AUTOSAR XML (schema 314)
package /ComponentType
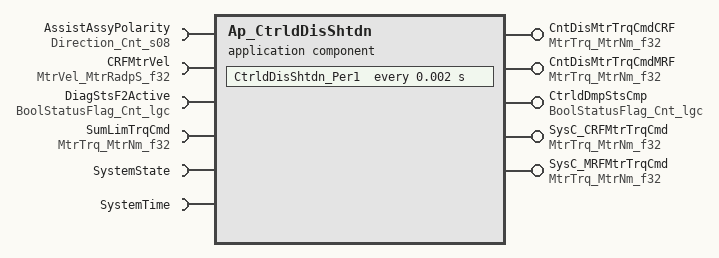
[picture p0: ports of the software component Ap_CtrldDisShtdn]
  application software component type Ap_CtrldDisShtdn
    5 x provide port:
      CntDisMtrTrqCmdCRF: unqueued-sender-com-spec{data-element=MtrNm_f32, can-invalidate=false, init-value=D_ZERO_ULS_F32}, provided-interface=MtrTrq_MtrNm_f32
      CntDisMtrTrqCmdMRF: unqueued-sender-com-spec{data-element=MtrNm_f32, can-invalidate=false, init-value=D_ZERO_ULS_F32}, provided-interface=MtrTrq_MtrNm_f32
      CtrldDmpStsCmp: unqueued-sender-com-spec{data-element=Cnt_lgc, can-invalidate=false, init-value=D_FALSE_CNT_LGC}, provided-interface=BoolStatusFlag_Cnt_lgc
      SysC_CRFMtrTrqCmd: unqueued-sender-com-spec{data-element=MtrNm_f32, can-invalidate=false, init-value=D_ZERO_ULS_F32}, provided-interface=MtrTrq_MtrNm_f32
      SysC_MRFMtrTrqCmd: unqueued-sender-com-spec{data-element=MtrNm_f32, can-invalidate=false, init-value=D_ZERO_ULS_F32}, provided-interface=MtrTrq_MtrNm_f32
    6 x require port:
      AssistAssyPolarity: unqueued-receiver-com-spec{data-element=Cnt_s08, init-value=D_ZERO_CNT_S8}, required-interface=Direction_Cnt_s08
      CRFMtrVel: unqueued-receiver-com-spec{data-element=MtrRadpS_f32, init-value=D_ZERO_ULS_F32}, required-interface=MtrVel_MtrRadpS_f32
      DiagStsF2Active: unqueued-receiver-com-spec{data-element=Cnt_lgc, init-value=D_FALSE_CNT_LGC}, required-interface=BoolStatusFlag_Cnt_lgc
      SumLimTrqCmd: unqueued-receiver-com-spec{data-element=MtrNm_f32, init-value=D_ZERO_ULS_F32}, required-interface=MtrTrq_MtrNm_f32
      SystemState: required-interface=SystemState
      SystemTime: required-interface=SystemTime
        required-com-specs:
          DtrmnElapsedTime_mS_u16
          DtrmnElapsedTime_mS_u32
          DtrmnElapsedTime_uS_u16
          DtrmnElapsedTime_uS_u32
          GetSystemTime_mS_u32
          GetSystemTime_uS_u32
  internal behavior Ap_CtrldDisShtdn_InternalBehavior: component=Ap_CtrldDisShtdn
    timing event TMT_CtrldDisShtdn_Per1: start-on-event=CtrldDisShtdn_Per1, period=0.002
    port-api-options:
      enable-take-address=false, indirect-api=false, port=AssistAssyPolarity
      enable-take-address=false, indirect-api=false, port=CntDisMtrTrqCmdCRF
      enable-take-address=false, indirect-api=false, port=CntDisMtrTrqCmdMRF
      enable-take-address=false, indirect-api=false, port=CRFMtrVel
      enable-take-address=false, indirect-api=false, port=CtrldDmpStsCmp
      enable-take-address=false, indirect-api=false, port=DiagStsF2Active
      enable-take-address=false, indirect-api=false, port=SumLimTrqCmd
      enable-take-address=false, indirect-api=false, port=SysC_CRFMtrTrqCmd
      enable-take-address=false, indirect-api=false, port=SysC_MRFMtrTrqCmd
      enable-take-address=false, indirect-api=false, port=SystemState
      enable-take-address=false, indirect-api=false, port=SystemTime
    runnable CtrldDisShtdn_Per1
      4 x data read access:
        READ_AssistAssyPolarity_Cnt_s08: data-element=AssistAssyPolarity.Cnt_s08
        READ_CRFMtrVel_MtrRadpS_f32: data-element=CRFMtrVel.MtrRadpS_f32
        READ_DiagStsF2Active_Cnt_lgc: data-element=DiagStsF2Active.Cnt_lgc
        READ_SumLimTrqCmd_MtrNm_f32: data-element=SumLimTrqCmd.MtrNm_f32
      5 x data write access:
        WRITE_CntDisMtrTrqCmdCRF_MtrNm_f32: data-element=CntDisMtrTrqCmdCRF.MtrNm_f32
        WRITE_CntDisMtrTrqCmdMRF_MtrNm_f32: data-element=CntDisMtrTrqCmdMRF.MtrNm_f32
        WRITE_CtrldDmpStsCmp_Cnt_lgc: data-element=CtrldDmpStsCmp.Cnt_lgc
        WRITE_SysC_CRFMtrTrqCmd_MtrNm_f32: data-element=SysC_CRFMtrTrqCmd.MtrNm_f32
        WRITE_SysC_MRFMtrTrqCmd_MtrNm_f32: data-element=SysC_MRFMtrTrqCmd.MtrNm_f32
      sync call SC_SystemTime_DtrmnElapsedTime_mS_u16: operation=SystemTime.DtrmnElapsedTime_mS_u16, timeout=0
      sync call SC_SystemTime_GetSystemTime_mS_u32: operation=SystemTime.GetSystemTime_mS_u32, timeout=0
  swc implementation Ap_CtrldDisShtdn_Implementation: behavior=Ap_CtrldDisShtdn_InternalBehavior
    code-descriptors:
      code Code: type=SRC
